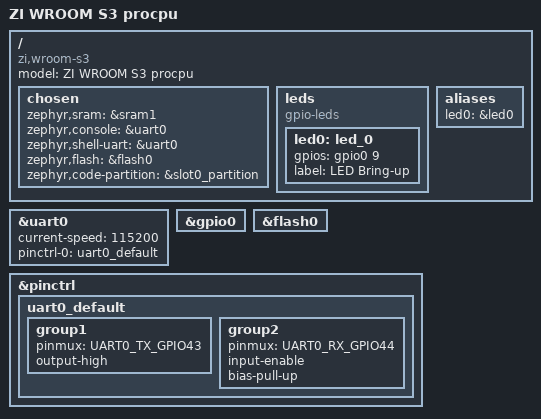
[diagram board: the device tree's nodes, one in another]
/*
 * Board kustom berbasis modul ESP32-S3-WROOM telanjang.
 *
 * Include SoC dtsi di bawah ini disalin dari struktur board
 * esp32s3_devkitc di source tree Zephyr. Nama file varian modul
 * (N8, N8R8, N16R8, dst) tergantung ukuran flash/PSRAM modul Anda dan
 * bisa berbeda antar rilis Zephyr -- cek dulu dengan:
 *
 *   find ~/zephyrproject/zephyr/dts -iname "esp32s3*"
 *
 * lalu sesuaikan path include kalau nama filenya beda dari yang saya
 * tulis di sini.
 */
/dts-v1/;

#include <espressif/esp32s3/esp32s3_procpu.dtsi>
#include <zephyr/dt-bindings/pinctrl/esp32s3-pinctrl.h>
#include <zephyr/dt-bindings/gpio/gpio.h>

/ {
	model = "ZI WROOM S3 procpu";
	compatible = "zi,wroom-s3";

	chosen {
		zephyr,sram = &sram1;
		zephyr,console = &uart0;
		zephyr,shell-uart = &uart0;
		zephyr,flash = &flash0;
		zephyr,code-partition = &slot0_partition;
	};

	/*
	 * LED bring-up tahap awal, sengaja beda pin dari WS2812 devkitc
	 * (GPIO48) supaya jelas ini devicetree board baru, bukan warisan.
	 */
	leds {
		compatible = "gpio-leds";
		led0: led_0 {
			gpios = <&gpio0 9 GPIO_ACTIVE_HIGH>;
			label = "LED Bring-up";
		};
	};

	aliases {
		led0 = &led0;
	};
};

&uart0 {
	status = "okay";
	current-speed = <115200>;
	pinctrl-0 = <&uart0_default>;
	pinctrl-names = "default";
};

&gpio0 {
	status = "okay";
};

&flash0 {
	status = "okay";
};

&pinctrl {
	uart0_default: uart0_default {
		group1 {
			pinmux = <UART0_TX_GPIO43>;
			output-high;
		};
		group2 {
			pinmux = <UART0_RX_GPIO44>;
			input-enable;
			bias-pull-up;
		};
	};
};
